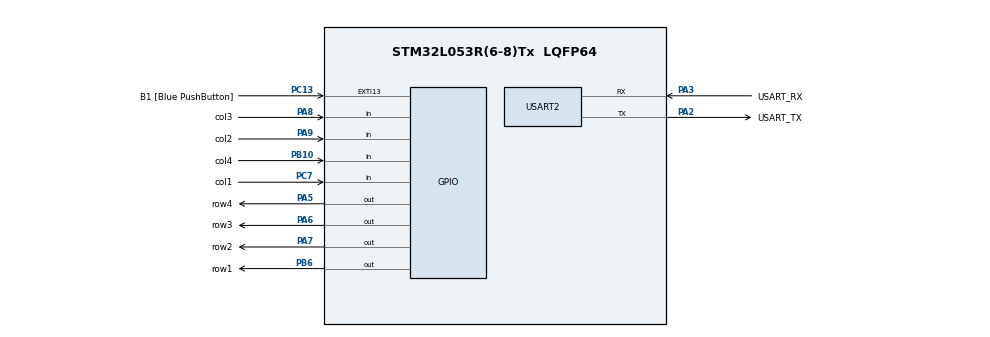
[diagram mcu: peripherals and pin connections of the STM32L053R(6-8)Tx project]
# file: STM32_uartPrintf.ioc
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Mcu.Family=STM32L0
Mcu.Name=STM32L053R(6-8)Tx
Mcu.Package=LQFP64
NVIC.USART2_IRQn=true\:0\:0\:false\:false\:true\:true\:true\:true
PA13.GPIO_Label=TMS
PA13.Mode=Serial_Wire
PA13.Signal=SYS_SWDIO
PA14.GPIO_Label=TCK
PA14.Mode=Serial_Wire
PA14.Signal=SYS_SWCLK
PA2.GPIO_Label=USART_TX
PA2.Mode=Asynchronous
PA2.Signal=USART2_TX
PA3.GPIO_Label=USART_RX
PA3.Mode=Asynchronous
PA3.Signal=USART2_RX
PA5.GPIO_Label=row4
PA5.PinState=GPIO_PIN_SET
PA5.Signal=GPIO_Output
PA6.GPIO_Label=row3
PA6.PinState=GPIO_PIN_SET
PA6.Signal=GPIO_Output
PA7.GPIO_Label=row2
PA7.PinState=GPIO_PIN_SET
PA7.Signal=GPIO_Output
PA8.GPIO_Label=col3
PA8.GPIO_PuPd=GPIO_PULLUP
PA8.Signal=GPIO_Input
PA9.GPIO_Label=col2
PA9.GPIO_PuPd=GPIO_PULLUP
PA9.Signal=GPIO_Input
PB10.GPIO_Label=col4
PB10.GPIO_PuPd=GPIO_PULLUP
PB10.Signal=GPIO_Input
PB6.GPIO_Label=row1
PB6.PinState=GPIO_PIN_SET
PB6.Signal=GPIO_Output
PB8.Signal=I2C1_SCL
PB9.Signal=I2C1_SDA
PC13.GPIO_Label=B1 [Blue PushButton]
PC13.GPIO_ModeDefaultEXTI=GPIO_MODE_IT_FALLING
PC13.Signal=GPXTI13
PC14-OSC32_IN.Mode=LSE-External-Oscillator
PC14-OSC32_IN.Signal=RCC_OSC32_IN
PC15-OSC32_OUT.Mode=LSE-External-Oscillator
PC15-OSC32_OUT.Signal=RCC_OSC32_OUT
PC7.GPIO_Label=col1
PC7.GPIO_PuPd=GPIO_PULLUP
PC7.Signal=GPIO_Input
PH0-OSC_IN.Mode=HSE-External-Clock-Source
PH0-OSC_IN.Signal=RCC_OSC_IN
PH1-OSC_OUT.Signal=RCC_OSC_OUT
ProjectManager.HeapSize=0x200
ProjectManager.StackSize=0x400
ProjectManager.TargetToolchain=STM32CubeIDE
RCC.AHBFreq_Value=16000000
RCC.APB1Freq_Value=16000000
RCC.APB1TimFreq_Value=16000000
RCC.APB2Freq_Value=16000000
RCC.APB2TimFreq_Value=16000000
RCC.HCLKFreq_Value=16000000
RCC.HSE_VALUE=8000000
RCC.HSI16_VALUE=16000000
RCC.HSI48_VALUE=48000000
RCC.HSI_VALUE=16000000
RCC.MSI_VALUE=2097000
RCC.SYSCLKFreq_VALUE=16000000
RCC.SYSCLKSource=RCC_SYSCLKSOURCE_HSI
RCC.VCOOutputFreq_Value=48000000
USART2.VirtualMode-Asynchronous=VM_ASYNC
board=NUCLEO-L053R8

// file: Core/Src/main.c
/* USER CODE BEGIN Header */
/**
  ******************************************************************************
  * @file           : main.c
  * @brief          : Main program body
  ******************************************************************************
  * @attention
  *
  * <h2><center>&copy; Copyright (c) 2020 STMicroelectronics.
  * All rights reserved.</center></h2>
  *
  * This software component is licensed by ST under BSD 3-Clause license,
  * the "License"; You may not use this file except in compliance with the
  * License. You may obtain a copy of the License at:
  *                        opensource.org/licenses/BSD-3-Clause
  *
  ******************************************************************************
  */
/* USER CODE END Header */
#include "main.h"
#include "usart.h"
#include "gpio.h"

/* USER CODE BEGIN Includes */
#include <stdio.h>
#include <retarget.h>
#include <getch.h>
/* USER CODE END Includes */

/* USER CODE BEGIN PV */

char key_char;
uint8_t keypad_flag = 0;

/* USER CODE END PV */

void SystemClock_Config(void);

int main(void)
{

  /* MCU Configuration--------------------------------------------------------*/

  /* Reset of all peripherals, Initializes the Flash interface and the Systick. */

  LL_APB2_GRP1_EnableClock(LL_APB2_GRP1_PERIPH_SYSCFG);
  LL_APB1_GRP1_EnableClock(LL_APB1_GRP1_PERIPH_PWR);

  /* System interrupt init*/

  /* Configure the system clock */
  SystemClock_Config();

  /* Initialize all configured peripherals */
  MX_GPIO_Init();
  MX_USART2_UART_Init();
  /* USER CODE BEGIN 2 */
  RetargetInit(USART2);
  getchInit();
  LL_USART_EnableIT_RXNE(USART2);
  LL_SYSTICK_EnableIT();

  /* USER CODE END 2 */

  /* Infinite loop */
  /* USER CODE BEGIN WHILE */
  while (1)
  {
//	if (kbhit()) //if one char received on USART2
//	{
//	  printf("Recu:%c\r\n", getch()); //print it
//	}
    /* USER CODE END WHILE */

    /* USER CODE BEGIN 3 */

	/*
	* This code checks for a key press. If no key has been processed (`keypad_flag` is false),
	* it scans the keypad. When a valid key is pressed, it prints the key and sets
	* `keypad_flag` to true to prevent multiple prints for the same press.
	*/
	if (!keypad_flag) {
		key_char = key_scan();
		if (key_char != '-') {
			printf("Touche presse: %c\r\n", key_char);
			keypad_flag = 1;
		}
	}

  }
  /* USER CODE END 3 */
}

void SystemClock_Config(void)
{
  LL_FLASH_SetLatency(LL_FLASH_LATENCY_0);
  while(LL_FLASH_GetLatency()!= LL_FLASH_LATENCY_0)
  {
  }
  LL_PWR_SetRegulVoltageScaling(LL_PWR_REGU_VOLTAGE_SCALE1);
  LL_RCC_HSI_Enable();

   /* Wait till HSI is ready */
  while(LL_RCC_HSI_IsReady() != 1)
  {

  }
  LL_RCC_HSI_SetCalibTrimming(16);
  LL_RCC_SetAHBPrescaler(LL_RCC_SYSCLK_DIV_1);
  LL_RCC_SetAPB1Prescaler(LL_RCC_APB1_DIV_1);
  LL_RCC_SetAPB2Prescaler(LL_RCC_APB2_DIV_1);
  LL_RCC_SetSysClkSource(LL_RCC_SYS_CLKSOURCE_HSI);

   /* Wait till System clock is ready */
  while(LL_RCC_GetSysClkSource() != LL_RCC_SYS_CLKSOURCE_STATUS_HSI)
  {

  }

  LL_Init1msTick(16000000);

  LL_SetSystemCoreClock(16000000);
  LL_RCC_SetUSARTClockSource(LL_RCC_USART2_CLKSOURCE_PCLK1);
}

void Error_Handler(void)
{
}

/************************ (C) COPYRIGHT STMicroelectronics *****END OF FILE****/
